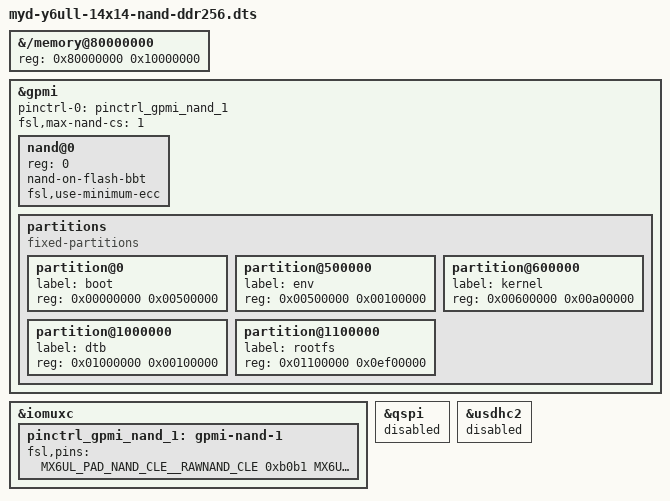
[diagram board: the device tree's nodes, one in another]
// SPDX-License-Identifier: GPL-2.0
//
// Copyright (C) 2016 Freescale Semiconductor, Inc.

#include "myd-y6ull-14x14.dts"

/*
 * DDR256 SKU (see myd_imx6ull_nand_ddr256_defconfig): shared myd-y6ul-14x14.dtsi
 * still describes 512 MiB; fix U-Boot FDT so arch memory fixup matches hardware.
 */
&{/memory@80000000} {
	reg = <0x80000000 0x10000000>;
};

/*
 * Match Linux myd-y6ull-14x14-nand.dts: DM NAND + mtd read <part> rely on the
 * same fixed-partitions as Linux / nandwrite targets, avoiding env-only tables.
 */
&gpmi {
	pinctrl-names = "default";
	pinctrl-0 = <&pinctrl_gpmi_nand_1>;
	fsl,max-nand-cs = <1>;
	status = "okay";

	nand@0 {
		reg = <0>;
		nand-on-flash-bbt;
		fsl,use-minimum-ecc;
	};

	partitions {
		compatible = "fixed-partitions";
		#address-cells = <1>;
		#size-cells = <1>;

		partition@0 {
			label = "boot";
			reg = <0x00000000 0x00500000>;
		};
		partition@500000 {
			label = "env";
			reg = <0x00500000 0x00100000>;
		};
		partition@600000 {
			label = "kernel";
			reg = <0x00600000 0x00a00000>;
		};
		partition@1000000 {
			label = "dtb";
			reg = <0x01000000 0x00100000>;
		};
		partition@1100000 {
			label = "rootfs";
			reg = <0x01100000 0x0ef00000>;
		};
	};
};

&iomuxc {
	pinctrl_gpmi_nand_1: gpmi-nand-1 {
		fsl,pins = <
			MX6UL_PAD_NAND_CLE__RAWNAND_CLE         0xb0b1
			MX6UL_PAD_NAND_ALE__RAWNAND_ALE         0xb0b1
			MX6UL_PAD_NAND_WP_B__RAWNAND_WP_B       0xb0b1
			MX6UL_PAD_NAND_READY_B__RAWNAND_READY_B 0xb000
			MX6UL_PAD_NAND_CE0_B__RAWNAND_CE0_B     0xb0b1
			MX6UL_PAD_NAND_CE1_B__RAWNAND_CE1_B     0xb0b1
			MX6UL_PAD_NAND_RE_B__RAWNAND_RE_B       0xb0b1
			MX6UL_PAD_NAND_WE_B__RAWNAND_WE_B       0xb0b1
			MX6UL_PAD_NAND_DATA00__RAWNAND_DATA00   0xb0b1
			MX6UL_PAD_NAND_DATA01__RAWNAND_DATA01   0xb0b1
			MX6UL_PAD_NAND_DATA02__RAWNAND_DATA02   0xb0b1
			MX6UL_PAD_NAND_DATA03__RAWNAND_DATA03   0xb0b1
			MX6UL_PAD_NAND_DATA04__RAWNAND_DATA04   0xb0b1
			MX6UL_PAD_NAND_DATA05__RAWNAND_DATA05   0xb0b1
			MX6UL_PAD_NAND_DATA06__RAWNAND_DATA06   0xb0b1
			MX6UL_PAD_NAND_DATA07__RAWNAND_DATA07   0xb0b1
		>;
	};
};

&qspi {
	status = "disabled";
};

&usdhc2 {
	status = "disabled";
};
